# thuasrv32 register map
Vendor: jesseopdenbrouw; Series: RISC-V; File version: 0.4.1
The THUAS RV32 RISC-V Processor
CPU: THUASRV32 r2p1, little endian, no MPU, no FPU, 4 interrupt priority bits
Registers are 32-bit, read-write, no defined reset value unless marked. A register's access mark holds for its fields unless they carry their own. Offsets are from the block's base; lines under a group give offsets from that group; [hi:lo] are bit positions; {n}, {i} and the like mark numbered series; 'fields as' and 'values as' point back to an identical list; <NAME> marks a mode.

## Memory map
0xF0000000 GPIO size 0x20 — General Purpose Input/Output Port
0xF0000100 UART1 size 0x10 — Primary Universal Asynchronous Receiver/Transmitter
0xF0000200 I2C1 size 0xC — Inter-Integrated Circuit 1
0xF0000300 I2C2 size 0xC — Inter-Integrated Circuit 2
0xF0000400 SPI1 size 0xC — Serial Peripheral interface 1
0xF0000500 SPI2 size 0xC — Serial Peripheral interface 2
0xF0000600 TIMER1 size 0x10
0xF0000700 TIMER2 size 0x20
0xF0000800 WDT size 0x8 — Watchdog Timer
0xF0000900 MSI size 0x4 — Machine Software Interrupt
0xF0000A00 MTIME size 0x10 — Machine Timer
0xF0000B00 UART2 size 0x10 — Secondary Universal Asynchronous Receiver/Transmitter
0xF0000C00 CRC size 0x14 — Cyclic Redundancy Check Module
0xF0000D00 ONEWIRE1 size 0x10 — 1-Wire Module 1

## Interrupts
3 MSI_IRQ (MSI)
7 MTIME_IRQ (MTIME)
18 EXTI_IRQ (GPIO)
19 UART2_BR_IRQ (UART2)
19 UART2_RX_IRQ (UART2)
19 UART2_TX_IRQ (UART2)
20 TIMER1_CMPT_IRQ (TIMER1)
21 TIMER2_CMPT_IRQ (TIMER2)
23 UART1_BR_IRQ (UART1)
23 UART1_RX_IRQ (UART1)
23 UART1_TX_IRQ (UART1)
24 I2C2_TC_IRQ (I2C2)
25 SPI2_TC_IRQ (SPI2)
26 I2C1_TC_IRQ (I2C1)
27 SPI1_TC_IRQ (SPI1)
31 WDT_IRQ (WDT)

## MTIME — Machine Timer
Base 0xF0000A00
0x00 MTIME — System Time Register - Low
0x04 MTIMEH — System Time Register - High
0x08 MTIMECMP — Time Compare Register - Low
0x0C MTIMECMPH — Time Compare Register - High

## GPIO — General Purpose Input/Output Port
Base 0xF0000000
0x00 PIN ro — Parallel Input Register
0x04 POUT — Parallel Output Register
0x08 PSET wo — Bit Set Register
0x0C PCLR wo — Bit Clear Register
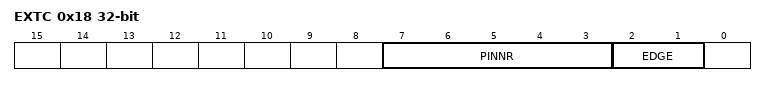
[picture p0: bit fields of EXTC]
0x18 EXTC — External Input Interrupt Control Register
  [7:3] PINNR — GPIO Pin Input Select
  [2:1] EDGE — Select Edge
0x1C EXTS — External Input Interrupt Status Register
  [0] DETECT — Edge Detected

## UART1 — Primary Universal Asynchronous Receiver/Transmitter
Base 0xF0000100
Same registers: UART2 0xF0000B00
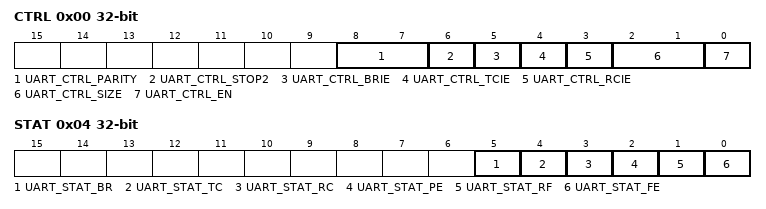
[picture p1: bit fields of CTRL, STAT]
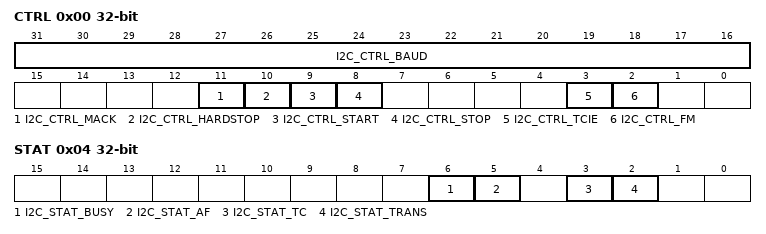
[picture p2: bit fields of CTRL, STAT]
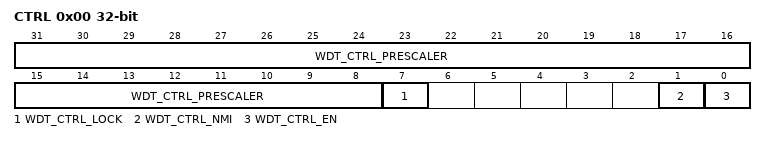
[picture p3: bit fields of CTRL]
0x00 CTRL — Control Register
  [8:7] UART_CTRL_PARITY — Parity
  [6] UART_CTRL_STOP2 — Two STOP Bits Enable
  [5] UART_CTRL_BRIE — Break Received Interrupt Enable
  [4] UART_CTRL_TCIE — Transmit Complete Interrupt Enable
  [3] UART_CTRL_RCIE — Receive Complete Interrupt Enable
  [2:1] UART_CTRL_SIZE — Data Size in Frame
  [0] UART_CTRL_EN — UART Enable Flag
0x04 STAT — Status Register
  [5] UART_STAT_BR — BREAK Detected
  [4] UART_STAT_TC — Transmit Complete
  [3] UART_STAT_RC — Receive Complete
  [2] UART_STAT_PE — Parity Error
  [1] UART_STAT_RF — Receive Failed
  [0] UART_STAT_FE — Frame Error
0x08 DATA
  [9:0] DATA — Data to Transmit or Receive
0x0C BAUD — Baud Rate Divisor Prescaler Register
  [15:0] PRESCALER — Baud Rate Prescaler

## I2C1 — Inter-Integrated Circuit 1
Base 0xF0000200
Same registers: I2C2 0xF0000300
0x00 CTRL — Control Register
  [31:16] I2C_CTRL_BAUD — I2C Baudrate Divisor
  [11] I2C_CTRL_MACK — I2C Master Acknowlegde Enable
  [10] I2C_CTRL_HARDSTOP — I2C Transmit Direct STOP Condition
  [9] I2C_CTRL_START — I2C Transmit START Condition
  [8] I2C_CTRL_STOP — I2C Transmit STOP Condition
  [3] I2C_CTRL_TCIE — I2C Transmit Complete Interrupt Enable
  [2] I2C_CTRL_FM — I2C Fast Mode Select
0x04 STAT — Status Register
  [6] I2C_STAT_BUSY — I2C Bus Busy
  [5] I2C_STAT_AF — I2C Acknowledge Failed
  [3] I2C_STAT_TC — I2C Tramission Complete
  [2] I2C_STAT_TRANS — I2C Tramission in Progress
0x08 DATA
  [7:0] I2C_DATA

## WDT — Watchdog Timer
Base 0xF0000800
0x00 CTRL — Control Register
  [31:8] WDT_CTRL_PRESCALER — Watchdog Prescaler
  [7] WDT_CTRL_LOCK — Watchdog Lock Enable
  [1] WDT_CTRL_NMI — Watchdog NMI Enable
  [0] WDT_CTRL_EN — Watchdog Enable
0x04 TRIG wo — Trigger Register
  [31:0] WDT_TRIG_PASSWORD — Password Field
